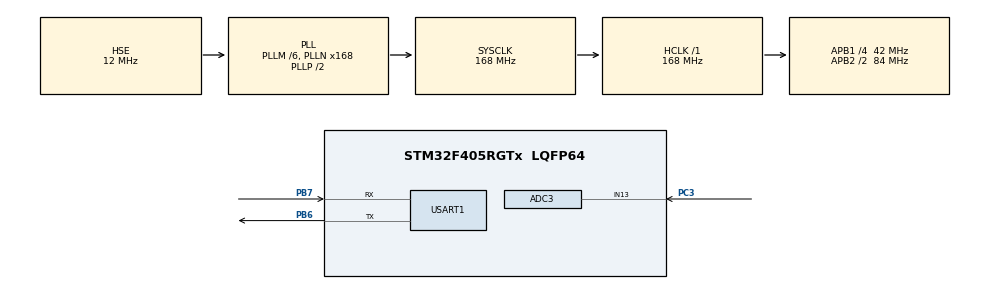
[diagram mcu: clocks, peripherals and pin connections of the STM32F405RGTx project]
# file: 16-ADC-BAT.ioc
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ADC1.Channel-0\#ChannelRegularConversion=ADC_CHANNEL_13
ADC1.ContinuousConvMode=ENABLE
ADC1.DMAContinuousRequests=ENABLE
ADC1.Mode=ADC_TRIPLEMODE_INTERL
ADC1.NbrOfConversionFlag=1
ADC1.Rank-0\#ChannelRegularConversion=1
ADC1.SamplingTime-0\#ChannelRegularConversion=ADC_SAMPLETIME_3CYCLES
ADC1.TwoSamplingDelay=ADC_TWOSAMPLINGDELAY_20CYCLES
ADC1.master=1
ADC2.Channel-0\#ChannelRegularConversion=ADC_CHANNEL_13
ADC2.DMAAccessMode=ADC_DMAACCESSMODE_2
ADC2.Mode=ADC_TRIPLEMODE_INTERL
ADC2.NbrOfConversionFlag=1
ADC2.Rank-0\#ChannelRegularConversion=1
ADC2.SamplingTime-0\#ChannelRegularConversion=ADC_SAMPLETIME_3CYCLES
ADC2.TwoSamplingDelay=ADC_TWOSAMPLINGDELAY_20CYCLES
ADC3.Channel-0\#ChannelRegularConversion=ADC_CHANNEL_13
ADC3.DMAAccessMode=ADC_DMAACCESSMODE_2
ADC3.Mode=ADC_TRIPLEMODE_INTERL
ADC3.NbrOfConversionFlag=1
ADC3.Rank-0\#ChannelRegularConversion=1
ADC3.SamplingTime-0\#ChannelRegularConversion=ADC_SAMPLETIME_3CYCLES
ADC3.TwoSamplingDelay=ADC_TWOSAMPLINGDELAY_20CYCLES
Dma.ADC1.0.Direction=DMA_PERIPH_TO_MEMORY
Dma.ADC1.0.FIFOMode=DMA_FIFOMODE_DISABLE
Dma.ADC1.0.Instance=DMA2_Stream0
Dma.ADC1.0.MemDataAlignment=DMA_MDATAALIGN_HALFWORD
Dma.ADC1.0.MemInc=DMA_MINC_ENABLE
Dma.ADC1.0.Mode=DMA_CIRCULAR
Dma.ADC1.0.PeriphDataAlignment=DMA_PDATAALIGN_HALFWORD
Dma.ADC1.0.PeriphInc=DMA_PINC_DISABLE
Dma.ADC1.0.Priority=DMA_PRIORITY_VERY_HIGH
Dma.Request0=ADC1
Mcu.Family=STM32F4
Mcu.Name=STM32F405RGTx
Mcu.Package=LQFP64
NVIC.ADC_IRQn=true\:0\:0\:false\:false\:true\:true\:true
NVIC.DMA2_Stream0_IRQn=true\:0\:0\:false\:false\:true\:false\:true
NVIC.PriorityGroup=NVIC_PRIORITYGROUP_2
PA13.Mode=Serial_Wire
PA13.Signal=SYS_JTMS-SWDIO
PA14.Mode=Serial_Wire
PA14.Signal=SYS_JTCK-SWCLK
PB6.Mode=Asynchronous
PB6.Signal=USART1_TX
PB7.Mode=Asynchronous
PB7.Signal=USART1_RX
PC3.Signal=ADCx_IN13
PH0-OSC_IN.Mode=HSE-External-Oscillator
PH0-OSC_IN.Signal=RCC_OSC_IN
PH1-OSC_OUT.Mode=HSE-External-Oscillator
PH1-OSC_OUT.Signal=RCC_OSC_OUT
ProjectManager.HeapSize=0x200
ProjectManager.StackSize=0x400
ProjectManager.TargetToolchain=MDK-ARM V5.27
RCC.48MHZClocksFreq_Value=84000000
RCC.AHBFreq_Value=168000000
RCC.APB1CLKDivider=RCC_HCLK_DIV4
RCC.APB1Freq_Value=42000000
RCC.APB1TimFreq_Value=84000000
RCC.APB2CLKDivider=RCC_HCLK_DIV2
RCC.APB2Freq_Value=84000000
RCC.APB2TimFreq_Value=168000000
RCC.CortexFreq_Value=168000000
RCC.HCLKFreq_Value=168000000
RCC.HSE_VALUE=12000000
RCC.HSI_VALUE=16000000
RCC.LSE_VALUE=32768
RCC.PLLM=6
RCC.PLLN=168
RCC.PLLSourceVirtual=RCC_PLLSOURCE_HSE
RCC.SYSCLKFreq_VALUE=168000000
RCC.SYSCLKSource=RCC_SYSCLKSOURCE_PLLCLK
RCC.VCOOutputFreq_Value=336000000
SH.ADCx_IN13.0=ADC3_IN13,IN13
SH.ADCx_IN13.1=ADC1_IN13,IN13
SH.ADCx_IN13.2=ADC2_IN13,IN13
USART1.VirtualMode=VM_ASYNC
board=custom

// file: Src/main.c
/* USER CODE BEGIN Header */
/**
  ******************************************************************************
  * @file           : main.c
  * @brief          : Main program body
  ******************************************************************************
  * @attention
  *
  * <h2><center>&copy; Copyright (c) 2020 STMicroelectronics.
  * All rights reserved.</center></h2>
  *
  * This software component is licensed by ST under BSD 3-Clause license,
  * the "License"; You may not use this file except in compliance with the
  * License. You may obtain a copy of the License at:
  *                        opensource.org/licenses/BSD-3-Clause
  *
  ******************************************************************************
  */
/* USER CODE END Header */
#include "main.h"
#include "adc.h"
#include "dma.h"
#include "usart.h"
#include "gpio.h"

/* USER CODE BEGIN Includes */
#include "stdio.h"
/* USER CODE END Includes */

/* USER CODE BEGIN PV */
uint16_t adc_buffer[100];
uint32_t adc_avg;
/* USER CODE END PV */

void SystemClock_Config(void);

/* USER CODE BEGIN 0 */
int fputc(int ch, FILE *f)
{
	HAL_UART_Transmit(&huart1,(uint8_t *)&ch,1,0xffff);
	return (ch);
}

void HAL_ADC_ConvCpltCallback(ADC_HandleTypeDef* hadc)
{
	uint8_t i;
	for(i=0;i<100;i++)
		adc_avg += adc_buffer[i];
	adc_avg /=100;
}
/* USER CODE END 0 */

int main(void)
{
  /* USER CODE BEGIN 1 */
	float Vp;//单片机引脚检测到的电压
	float Vb;//电池电压
  /* USER CODE END 1 */

  /* MCU Configuration--------------------------------------------------------*/

  /* Reset of all peripherals, Initializes the Flash interface and the Systick. */
  HAL_Init();

  /* Configure the system clock */
  SystemClock_Config();

  /* Initialize all configured peripherals */
  MX_GPIO_Init();
  MX_DMA_Init();
  MX_ADC1_Init();
  MX_ADC2_Init();
  MX_ADC3_Init();
  MX_USART1_UART_Init();
  /* USER CODE BEGIN 2 */
	HAL_ADC_Start(&hadc2);
	HAL_ADC_Start(&hadc3);
	HAL_ADCEx_MultiModeStart_DMA(&hadc1,(uint32_t*)adc_buffer,100);
  /* USER CODE END 2 */

  /* Infinite loop */
  /* USER CODE BEGIN WHILE */
  while (1)
  {
		Vp = (float)(adc_avg*0.0008f); //0.0008056640625 = 3.3/4096
		Vb = (float)Vp*9.2f;//Vp = Vb/(R1+R2)*R2
		printf("%d\r\n",adc_avg);
		printf("Vp = %.2f\r\n",Vp);
		printf("Vb = %.2f\r\n",Vb);
		HAL_Delay(1000);
    /* USER CODE END WHILE */

  }
}

void SystemClock_Config(void)
{
  RCC_OscInitTypeDef RCC_OscInitStruct = {0};
  RCC_ClkInitTypeDef RCC_ClkInitStruct = {0};

  /** Configure the main internal regulator output voltage
  */
  __HAL_RCC_PWR_CLK_ENABLE();
  __HAL_PWR_VOLTAGESCALING_CONFIG(PWR_REGULATOR_VOLTAGE_SCALE1);
  /** Initializes the RCC Oscillators according to the specified parameters
  * in the RCC_OscInitTypeDef structure.
  */
  RCC_OscInitStruct.OscillatorType = RCC_OSCILLATORTYPE_HSE;
  RCC_OscInitStruct.HSEState = RCC_HSE_ON;
  RCC_OscInitStruct.PLL.PLLState = RCC_PLL_ON;
  RCC_OscInitStruct.PLL.PLLSource = RCC_PLLSOURCE_HSE;
  RCC_OscInitStruct.PLL.PLLM = 6;
  RCC_OscInitStruct.PLL.PLLN = 168;
  RCC_OscInitStruct.PLL.PLLP = RCC_PLLP_DIV2;
  RCC_OscInitStruct.PLL.PLLQ = 4;
  if (HAL_RCC_OscConfig(&RCC_OscInitStruct) != HAL_OK)
  {
    Error_Handler();
  }
  /** Initializes the CPU, AHB and APB buses clocks
  */
  RCC_ClkInitStruct.ClockType = RCC_CLOCKTYPE_HCLK|RCC_CLOCKTYPE_SYSCLK
                              |RCC_CLOCKTYPE_PCLK1|RCC_CLOCKTYPE_PCLK2;
  RCC_ClkInitStruct.SYSCLKSource = RCC_SYSCLKSOURCE_PLLCLK;
  RCC_ClkInitStruct.AHBCLKDivider = RCC_SYSCLK_DIV1;
  RCC_ClkInitStruct.APB1CLKDivider = RCC_HCLK_DIV4;
  RCC_ClkInitStruct.APB2CLKDivider = RCC_HCLK_DIV2;

  if (HAL_RCC_ClockConfig(&RCC_ClkInitStruct, FLASH_LATENCY_5) != HAL_OK)
  {
    Error_Handler();
  }
}

void Error_Handler(void)
{
}

/************************ (C) COPYRIGHT STMicroelectronics *****END OF FILE****/
